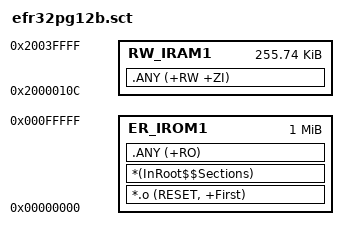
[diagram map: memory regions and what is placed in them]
; *************************************************************
; *** Scatter-Loading Description File generated by uVision ***
; *************************************************************

LR_IROM1 0x00000000 0x00100000  {    ; load region size_region
  ER_IROM1 0x00000000 0x00100000  {  ; load address = execution address
   *.o (RESET, +First)
   *(InRoot$$Sections)
   .ANY (+RO)
  }
  RW_IRAM1 0x2000010C 0x0003FEF4  {  ; RW data
   .ANY (+RW +ZI)
  }
}

